# max32570 register map
Vendor: Maxim-Integrated; Series: ARMCM4; File version: 1.0
CPU: CM4 r2p1, little endian, MPU, FPU, 3 interrupt priority bits
Registers are 32-bit, read-write, reset 0x0 unless marked. A register's access mark holds for its fields unless they carry their own. Offsets are from the block's base; [hi:lo] are bit positions; {n}, {i} and the like mark numbered series; 'fields as' and 'values as' point back to an identical list.

## SMON — The Security Monitor block used to monitor system threat conditions.
Base 0x40004000
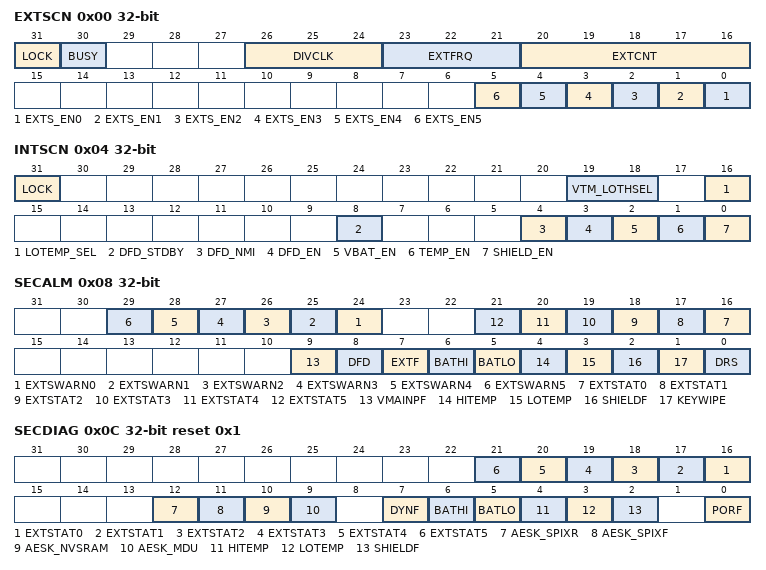
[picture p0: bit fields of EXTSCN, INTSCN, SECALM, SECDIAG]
0x00 EXTSCN (reset mask 0x3800FFC0) — External Sensor Control Register.
  [31] LOCK — Lock Register. Once locked, the EXTSCN register can no longer be modified. Only a battery disconnect will clear this bit. VBAT powers this register.
    0=unlocked; 1=locked
  [30] BUSY ro — Busy. This bit is set to 1 by hardware after EXTSCN register is written to. This bit is automatically cleared to 0 after this register information has been transferred to the security monitor domain.
    0=idle; 1=busy (Update in Progress.)
  [26:24] DIVCLK — Clock Divide. These bits are used to divide the 8KHz input clock. The resulting divided clock is used for all logic within the Security Monitor Block. Note: If the input clock is divided with these bits, the error count threshold table and output frequency will be affected accordingly with the same divide factor.
    0=div1 (Divide by 1 (8000 Hz).); 1=div2 (Divide by 2 (4000 Hz).); 2=div4 (Divide by 4 (2000 Hz).); 3=div8 (Divide by 8 (1000 Hz).); 4=div16 (Divide by 16 (500 Hz).); 5=div32 (Divide by 32 (250 Hz).); 6=div64 (Divide by 64 (125 Hz).)
  [23:21] EXTFRQ — External Sensor Frequency. These bits define the frequency at which the external sensors are clocked to/from the EXTS_IN and EXTS_OUT pair.
    0=freq2000Hz (Div 4 (2000Hz).); 1=freq1000Hz (Div 8 (1000Hz).); 2=freq500Hz (Div 16 (500Hz).); 3=freq250Hz (Div 32 (250Hz).); 4=freq125Hz (Div 64 (125Hz).); 5=freq63Hz (Div 128 (63Hz).); 6=freq31Hz (Div 256 (31Hz).)
  [20:16] EXTCNT — External Sensor Error Counter. These bits set the number of external sensor accepted mismatches that have to occur within a single bit period before an external sensor alarm is triggered.
  [n] EXTS_EN{n} (n=0..5) — External Sensor Enable for input/output pair {n}.
    0=dis (Disable.); 1=en (Enable.)
0x04 INTSCN (reset mask 0x7F00FFF7) — Internal Sensor Control Register.
  [31] LOCK — Lock Register. Once locked, the INTSCN register can no longer be modified. Only a battery disconnect will clear this bit. VBAT powers this register.
    0=unlocked; 1=locked
  [19:18] VTM_LOTHSEL — VTM Low Threshold Detection
    0=1_6V; 1=2_2V; 2=2_8V
  [16] LOTEMP_SEL — Low Temperature Detection Select.
    0=neg50C (-50 degrees C.); 1=neg30C (-30 degrees C.)
  [8] DFD_STDBY — Digital Fault Dector Stand by Enable
  [4] DFD_NMI — Digital Fault NMI Enable
  [3] DFD_EN — Digital Fault Dector Enable
  [2] VBAT_EN — Battery Monitor Enable.
    0=dis (Disable.); 1=en (Enable.)
  [1] TEMP_EN — Temperature Sensor Enable.
    0=dis (Disable.); 1=en (Enable.)
  [0] SHIELD_EN — Die Shield Enable.
    0=dis (Disable.); 1=en (Enable.)
0x08 SECALM reset not defined — Security Alarm Register.
  [n+24] EXTSWARN{n} (n=0..5) — External Sensor {n} Warning Ready flag. The tamper detect warning flags are set, regardless of whether the external sensors are enabled.
    0=noEvent (The event has not occurred.); 1=occurred (The event has occurred.)
  [n+16] EXTSTAT{n} (n=0..5) — External Sensor {n} Detect. The tamper detect is only active when it is enabled. This bits needs to be cleared in software after a tamper event to re-arm the sensor.
    values as EXTSWARN0
  [9] VMAINPF — VMAIN Power Fail Flag.
    values as EXTSWARN0
  [8] DFD — Digital Fault Detector.
    values as EXTSWARN0
  [7] EXTF — External Sensor Flag. This bit is set to 1 when any of the EXTSTAT bits are set.
    values as EXTSWARN0
  [6] BATHI — Battery Overvoltage Detect.
    values as EXTSWARN0
  [5] BATLO — Battery Undervoltage Detect.
    values as EXTSWARN0
  [4] HITEMP — High Temperature Detect.
    values as EXTSWARN0
  [3] LOTEMP — Low Temperature Detect.
    values as EXTSWARN0
  [2] SHIELDF — Die Shield Flag.
    values as EXTSWARN0
  [1] KEYWIPE — Key Wipe Trigger. Set to 1 to initiate a wipe of the AES key register. It does not reset the part, or log a timestamp. AES and DES registers are not affected by this bit. This bit is automatically cleared to 0 after the keys have been wiped.
    0=complete (No operation/complete.); 1=Start operation
  [0] DRS — Destructive Reset Trigger. Setting this bit will generate a DRS. This bit is self-cleared by hardware.
    0=complete (No operation/complete.); 1=Start operation
0x0C SECDIAG reset 0x1 (reset mask 0xFFC0FE02) — Security Diagnostic Register.
  [n+16] EXTSTAT{n} ro (n=0..5) — External Sensor {n} Detect.
    values as SECALM.EXTSWARN0
  [12] AESK_SPIXR ro — SPIXR 128-Bit AES Key Cleared. This field is set to 1 by hardware if the SPIXR 128-bit AES key is zero. This field resets to 1 on a POR.
    0=nonzero (Key is non-zero.); 1=zero (Key is zero.)
  [11] AESK_SPIXF ro — SPIXF 128-Bit AES Key Cleared. This field is set to 1 by hardware if the SPIXR 128-bit AES key is zero. This field resets to 1 on a POR.
    0=nonzero (Key is non-zero.); 1=zero (Key is zero.)
  [10] AESK_NVSRAM ro — NVSRAM 256-bit AES Key Cleared. This field is set to 1 by hardware if the NVSRAM AES key is zero. This field resets to 1 on a POR.
    0=nonzero (Key is non-zero.); 1=zero (Key is zero.)
  [9] AESK_MDU ro — AES Key Transfer. This bit is set to 1 when AES MDU Key has been transferred from the TRNG to the battery backed AES key register. This bit can only be reset by a BOR.
    0=incomplete (Key has not been transferred.); 1=complete (Key has been transferred.)
  [7] DYNF ro — Dynamic Sensor Flag. This bit is set to 1 when any of the EXTSTAT bits are set.
    values as SECALM.EXTSWARN0
  [6] BATHI ro — Battery Overvoltage Detect.
    values as SECALM.EXTSWARN0
  [5] BATLO ro — Battery Undervoltage Detect.
    values as SECALM.EXTSWARN0
  [4] HITEMP ro — High Temperature Detect.
    values as SECALM.EXTSWARN0
  [3] LOTEMP ro — Low Temperature Detect.
    values as SECALM.EXTSWARN0
  [2] SHIELDF ro — Die Shield Flag.
    values as SECALM.EXTSWARN0
  [0] PORF — Power-On-Reset Flag. This bit is set once the power supply is conneted.
    values as SECALM.EXTSWARN0
0x10 DLRTC ro reset not defined — DRS Log RTC Value. This register contains the 32 bit value in the RTC second register when the last DRS event occurred.
  [31:0] DLRTC — DRS Log RTC Value. This register contains the 32 bit value in the RTC second register when the last DRS event occured.
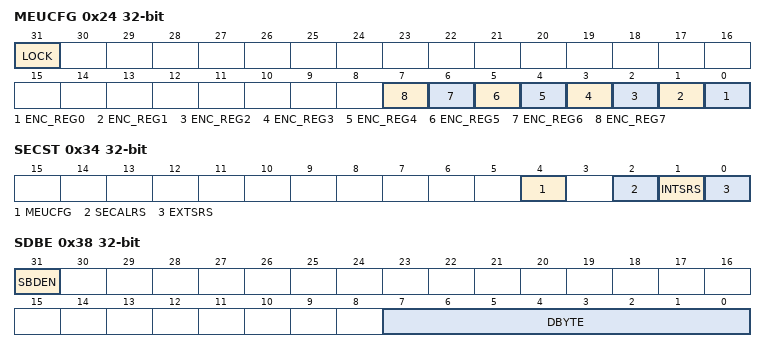
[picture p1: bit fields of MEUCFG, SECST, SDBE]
0x24 MEUCFG reset not defined — MEU Configuration
  [31] LOCK
  [n] ENC_REG{n} (n=0..7) — NVSRAM Encryption Enable Region {n}. Setting this field to 1 enables encryption using the MEU of region {n} of the NVSRAM.
    0=plaintext; 1=encrypted
0x34 SECST ro — Security Monitor Status Register.
  [4] MEUCFG — MEU Configuration Register Status.
    0=Normal Operation; 1=busy
  [2] SECALRS — Security Alarm Register Status.
    0=allowed (Access authorized.); 1=notAllowed (Access not authorized.)
  [1] INTSRS — Internal Sensor Control Register Status.
    values as SECALRS
  [0] EXTSRS — External Sensor Control Register Status.
    values as SECALRS
0x38 SDBE — Security Monitor Self Destruct Byte.
  [31] SBDEN — Self-Destruct Byte Enable.
  [7:0] DBYTE ro — Self Destruct Byte
